VERSION ""

NS_ :

BS_:

BU_:

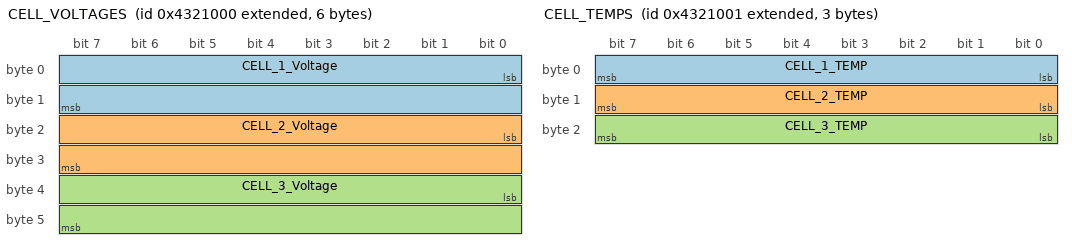
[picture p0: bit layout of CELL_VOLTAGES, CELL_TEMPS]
BO_ 2217873408 CELL_VOLTAGES: 6 LVBMS
	SG_ CELL_1_Voltage : 0|16@1+ (0.000977,0) [0|0] "V" LVBMS
	SG_ CELL_2_Voltage : 16|16@1+ (0.000977,0) [0|0] "V" LVBMS
	SG_ CELL_3_Voltage : 32|16@1+ (0.000977,0) [0|0] "V" LVBMS

BO_ 2217873409 CELL_TEMPS: 3 LVBMS
	SG_ CELL_1_TEMP : 0|8@1- (1,0) [0|0] "'C" LVBMS
	SG_ CELL_2_TEMP : 8|8@1- (1,0) [0|0] "'C" LVBMS
	SG_ CELL_3_TEMP : 16|8@1- (1,0) [0|0] "'C" LVBMS

BO_ 2217873410 Current: 2 LVBMS
	SG_ Current : 0|16@1- (0.001953125,0) [0|0] "A" LVBMS

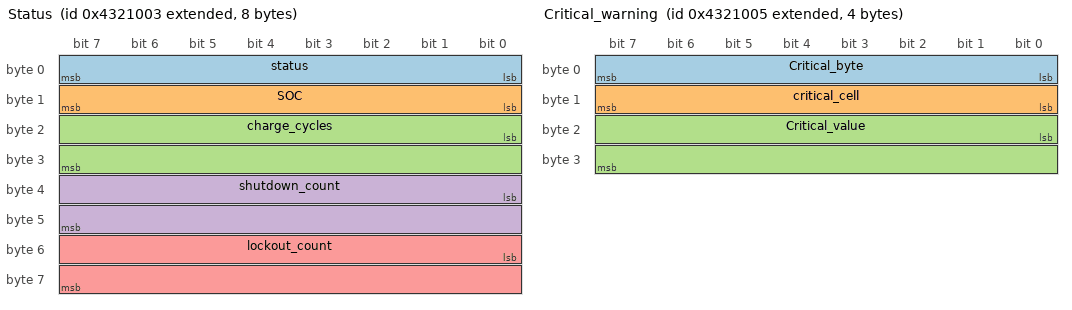
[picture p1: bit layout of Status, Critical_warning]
BO_ 2217873411 Status: 8 LVBMS
	SG_ status : 0|8@1+ (1,0) [0|0] "" LVBMS
	SG_ SOC : 8|8@1+ (1,0) [0|0] "" LVBMS
	SG_ charge_cycles : 16|16@1+ (1,0) [0|0] "" LVBMS
	SG_ shutdown_count : 32|16@1+ (1,0) [0|0] "" LVBMS
	SG_ lockout_count : 48|16@1+ (1,0) [0|0] "" LVBMS

BO_ 2217873412 Empty_warning: 0 LVBMS
	SG_ t : 0|1@1+ (0,0) [0|0] "" LVBMS

BO_ 2217873413 Critical_warning: 4 LVBMS
	SG_ Critical_byte : 0|8@1+ (1,0) [0|0] "" LVBMS
	SG_ critical_cell : 8|8@1+ (1,0) [0|0] "" LVBMS
	SG_ Critical_value : 16|16@1+ (1,0) [0|0] "" LVBMS

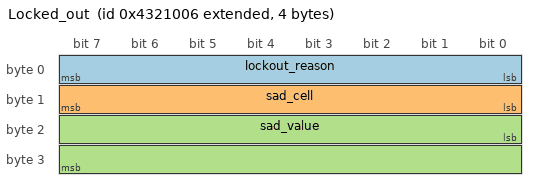
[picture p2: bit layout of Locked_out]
BO_ 2217873414 Locked_out: 4 LVBMS
	SG_ lockout_reason : 0|8@1+ (1,0) [0|0] "" LVBMS
	SG_ sad_cell : 8|8@1+ (1,0) [0|0] "" LVBMS
	SG_ sad_value : 16|16@1+ (1,0) [0|0] "" LVBMS

BO_ 2147483648 : 0 Vector__XXX
	SG_  : 0|0@1+ (0,0) [0|0] "" Vector__XXX

BO_ 2147483648 : 0 Vector__XXX
	SG_  : 0|0@1+ (0,0) [0|0] "" Vector__XXX

BO_ 2147483648 : 0 Vector__XXX
	SG_  : 0|0@1+ (0,0) [0|0] "" Vector__XXX

BO_ 2147483648 : 0 Vector__XXX
	SG_  : 0|0@1+ (0,0) [0|0] "" Vector__XXX

BO_ 2147483648 : 0 Vector__XXX
	SG_  : 0|0@1+ (0,0) [0|0] "" Vector__XXX

BA_DEF_ SG_  "SPN" INT 0 524287;
BA_DEF_ BO_  "VFrameFormat" ENUM  "StandardCAN","ExtendedCAN","reserved","J1939PG";
BA_DEF_  "DatabaseVersion" STRING ;
BA_DEF_  "BusType" STRING ;
BA_DEF_  "ProtocolType" STRING ;
BA_DEF_  "DatabaseCompiler" STRING ;
BA_DEF_DEF_  "SPN" 0;
BA_DEF_DEF_  "VFrameFormat" "J1939PG";
BA_DEF_DEF_  "DatabaseVersion" "DEMO PLUS";
BA_DEF_DEF_  "BusType" "";
BA_DEF_DEF_  "ProtocolType" "";
BA_DEF_DEF_  "DatabaseCompiler" "";
BA_ "ProtocolType" "J1939";
BA_ "BusType" "CAN";
BA_ "DatabaseCompiler" "CSS ELECTRONICS (WWW.CSSELECTRONICS.COM)";
BA_ "DatabaseVersion" "1.0.0";
BA_ "SPN" SG_ 2364540158 EngineSpeed 190;
BA_ "SPN" SG_ 2566844926 WheelBasedVehicleSpeed 84;

CM_ SG_ 2217873414 sad_value "temp: *1, Current *0.000977-32.768, Voltage: *0.000977";
CM_ SG_ 2217873411 status "0 - Powered down, 1 - Discharging, 2 - Charging, 3 - Empty, 4 - Fully charged,5 - Locked out";
CM_ SG_ 2217873413 Critical_byte "1 - voltage, 2 - temp, 3 - current";
CM_ SG_ 2217873413 Critical_value "temp: *1, Current *0.000977-32.768, Voltage: *0.000977";
